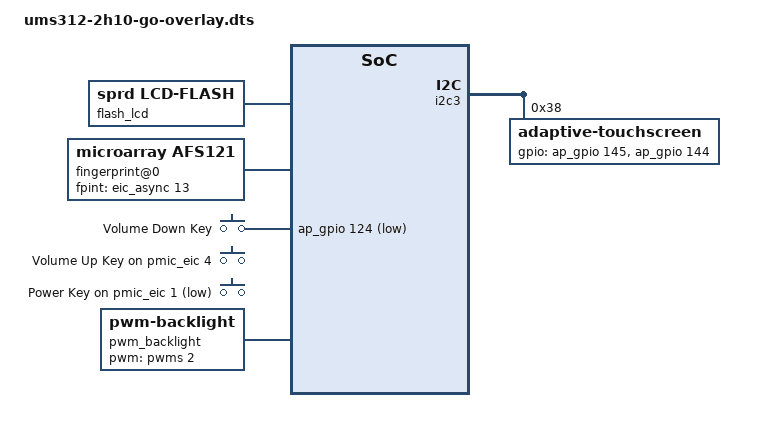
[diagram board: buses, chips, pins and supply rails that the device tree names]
/dts-v1/;
/plugin/;

#include <dt-bindings/input/input.h>
#include <dt-bindings/gpio/gpio.h>

/ {
	fragment {
		target-path = "/";
		__overlay__ {
			flash_lcd: flash-lcd {
				compatible = "sprd,lcd-flash";
				sprd,dpu = <&dpu>;
				sprd,backlight = <&pwm_backlight>;
				status = "okay";
			};

			fingerprint@0 {
				compatible = "microarray,afs121";
				fpint-gpios = <&eic_async 13 0>;
			};

			gpio-keys {
				compatible = "gpio-keys";

				key-volumedown {
					label = "Volume Down Key";
					linux,code = <KEY_VOLUMEDOWN>;
					gpios = <&ap_gpio 124 GPIO_ACTIVE_LOW>;
					debounce-interval = <2>;
					wakeup-source;
				};

				key-volumeup {
					label = "Volume Up Key";
					linux,code = <KEY_VOLUMEUP>;
					gpios = <&pmic_eic 4 GPIO_ACTIVE_HIGH>;
					debounce-interval = <2>;
					wakeup-source;
				};

				key-power {
					label = "Power Key";
					linux,code = <KEY_POWER>;
					gpios = <&pmic_eic 1 GPIO_ACTIVE_LOW>;
					debounce-interval = <2>;
					wakeup-source;
				};
			};

			pwm_backlight: sprd_backlight {
				compatible = "pwm-backlight";
				pwms = <&pwms 2 40000>;
				pwm-names = "backlight";
				brightness-levels = <
						  2   2   2   2   2   2   2   2
					  2   2   2   3   4   5   6   7   8   9
					 10  11  12  13  14  15  16  17  18  19
					 20  21  22  23  24  25  26  27  28  29
					 30  31  32  33  34  35  36  37  38  39
					 40  41  42  43  44  45  46  47  48  49
					 50  51  52  53  54  55  56  57  58  59
					 60  61  62  63  64  65  66  67  68  69
					 70  71  72  73  74  75  76  77  78  79
					 80  81  82  83  84  85  86  87  88  89
					 90  91  92  93  94  95  96  97  98  99
					100 101 102 103 104 105 106 107 108 109
					110 111 112 113 114 115 116 117 118 119
					120 121 122 123 124 125 126 127 128 129
					130 131 132 133 134 135 136 137 138 139
					140 141 142 143 144 145 146 147 148 149
					150 151 152 153 154 155 156 157 158 159
					160 161 162 163 164 165 166 167 168 169
					170 171 172 173 174 175 176 177 178 179
					180 181 182 183 184 185 186 187 188 189
					190 191 192 193 194 195 196 197 198 199
					200 201 202 203 204 205 206 207 208 209
					210 211 212 213 214 215 216 217 218 219
					220 221 222 223 224 225 226 227 228 229
					230 231 232 233 234 235 236 237 238 239
					240 241 242 243 244 245 246 247
					>;
				default-brightness-level = <33>;
			};
		};
	};
};

&reserved_memory {

	fd_reserved: face-mem@fd1c0000{
		reg = <0xfd1c0000 0x01e00000>;
	};
};

&i2c3 {
	status = "okay";

	adaptive-touchscreen@38 {
		compatible = "adaptive-touchscreen";
		reg = <0x38>;
		gpios = <&ap_gpio 145 GPIO_ACTIVE_HIGH
			&ap_gpio 144 GPIO_ACTIVE_HIGH>;
		controller = "focaltech,FT5436";
		virtualkeys = <580 60 1320 60 45
				172 360 1320 60 45
				158 600 1320 60 45>;
		private-data {
			a8 = /bits/ 8 <0x5a>;
		};
	};
};

&panel {
	sprd,backlight = <&pwm_backlight>;
};

&ddr_dfs {
	sprd-scene = "boost", "lcdon", "lcdoff", "camlow",
		"camhigh", "camveryhigh";
	sprd-freq = <933 512 256 384 512 933>;
};
